# ATmega162 register map
Vendor: Atmel; File version: 1.0
CPU: other r0p0, little endian, no MPU, no FPU, 4 interrupt priority bits
Registers are 8-bit, read-write, reset 0x0 unless marked. A register's access mark holds for its fields unless they carry their own. Offsets are from the block's base; [hi:lo] are bit positions.

## TC3 — Timer/Counter, 16-bit
Base 0x0000007C
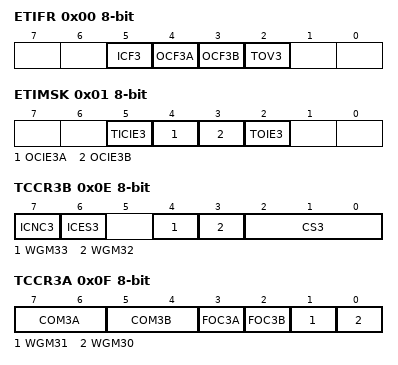
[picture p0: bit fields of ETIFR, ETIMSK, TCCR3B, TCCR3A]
0x00 ETIFR — Extended Timer/Counter Interrupt Flag register
  [5] ICF3 — Input Capture Flag 3
  [4] OCF3A — Output Compare Flag 3A
  [3] OCF3B — Output Compare Flag 3B
  [2] TOV3 — Timer/Counter3 Overflow Flag
0x01 ETIMSK — Extended Timer/Counter Interrupt Mask Register
  [5] TICIE3 — Timer/Counter3 Input Capture Interrupt Enable
  [4] OCIE3A — Timer/Counter3 Output CompareA Match Interrupt Enable
  [3] OCIE3B — Timer/Counter3 Output CompareB Match Interrupt Enable
  [2] TOIE3 — Timer/Counter3 Overflow Interrupt Enable
0x04 ICR3 16-bit (reset mask 0xFF) — Timer/Counter3 Input Capture Register Bytes
0x08 OCR3B 16-bit (reset mask 0xFF) — Timer/Counte3 Output Compare Register B Bytes
0x0A OCR3A 16-bit (reset mask 0xFF) — Timer/Counter3 Output Compare Register A Bytes
0x0C TCNT3 16-bit (reset mask 0xFF) — Timer/Counter3 Bytes
0x0E TCCR3B — Timer/Counter3 Control Register B
  [7] ICNC3 — Input Capture 3 Noise Canceler
  [6] ICES3 — Input Capture 3 Edge Select
  [4] WGM33 — Waveform Generation Mode
  [3] WGM32 — Waveform Generation Mode
  [2:0] CS3 — Clock Select3 bits
    0=No Clock Source (Stopped); 1=Running, No Prescaling; 2=Running, CLK/8; 3=Running, CLK/64; 4=Running, CLK/256; 5=Running, CLK/1024; 6=Running, CLK/16; 7=Running, CLK/32
0x0F TCCR3A — Timer/Counter3 Control Register A
  [7:6] COM3A — Compare Output Mode 3A, bits
  [5:4] COM3B — Compare Output Mode 3B, bits
  [3] FOC3A — Force Output Compare for Channel A
  [2] FOC3B — Force Output Compare for Channel B
  [1] WGM31 — Waveform Generation Mode
  [0] WGM30 — Waveform Generation Mode

## USART0 — USART
Base 0x00000029
0x00 UBRR0L — USART Baud Rate Register Low Byte
  [7:0] UBRR0 — USART Baud Rate Register Low bits
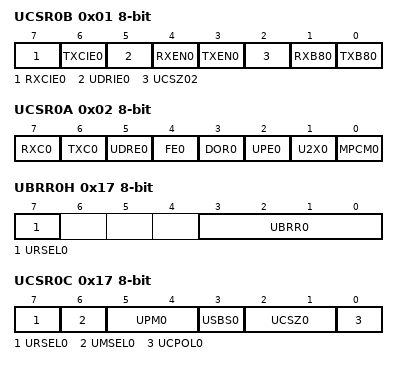
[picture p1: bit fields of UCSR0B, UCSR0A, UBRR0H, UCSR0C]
0x01 UCSR0B — USART Control and Status Register B
  [7] RXCIE0 — RX Complete Interrupt Enable
  [6] TXCIE0 — TX Complete Interrupt Enable
  [5] UDRIE0 — USART Data register Empty Interrupt Enable
  [4] RXEN0 — Receiver Enable
  [3] TXEN0 — Transmitter Enable
  [2] UCSZ02 — Character Size
  [1] RXB80 — Receive Data Bit 8
  [0] TXB80 — Transmit Data Bit 8
0x02 UCSR0A — USART Control and Status Register A
  [7] RXC0 — USART Receive Complete
  [6] TXC0 — USART Transmitt Complete
  [5] UDRE0 — USART Data Register Empty
  [4] FE0 — Framing Error
  [3] DOR0 — Data overRun
  [2] UPE0 — Parity Error
  [1] U2X0 — Double the USART transmission speed
  [0] MPCM0 — Multi-processor Communication Mode
0x03 UDR0 — USART I/O Data Register
0x17 UBRR0H — USART Baud Rate Register High Byte
  [7] URSEL0 — Register Select
  [3:0] UBRR0 — USART Baud Rate Register High bits
0x17 UCSR0C — USART Control and Status Register C
  [7] URSEL0 — Register Select
  [6] UMSEL0 — USART Mode Select
    0=Asynchronous Operation; 1=Synchronous Operation
  [5:4] UPM0 — Parity Mode Bits
    0=Disabled; 2=Enabled, Even Parity; 3=Enabled, Odd Parity
  [3] USBS0 — Stop Bit Select
    0=1-bit; 1=2-bit
  [2:1] UCSZ0 — Character Size
  [0] UCPOL0 — Clock Polarity

## USART1 — USART
Base 0x00000020
0x00 UBRR1L — USART Baud Rate Register Low Byte
  [7:0] UBRR1 — USART Baud Rate Register Low bits
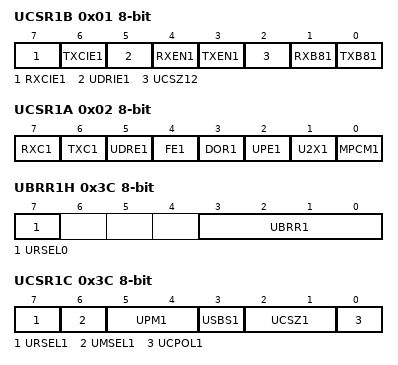
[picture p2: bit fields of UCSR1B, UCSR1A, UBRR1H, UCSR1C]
0x01 UCSR1B — USART Control and Status Register B
  [7] RXCIE1 — RX Complete Interrupt Enable
  [6] TXCIE1 — TX Complete Interrupt Enable
  [5] UDRIE1 — USART Data register Empty Interrupt Enable
  [4] RXEN1 — Receiver Enable
  [3] TXEN1 — Transmitter Enable
  [2] UCSZ12 — Character Size
  [1] RXB81 — Receive Data Bit 8
  [0] TXB81 — Transmit Data Bit 8
0x02 UCSR1A — USART Control and Status Register A
  [7] RXC1 — USART Receive Complete
  [6] TXC1 — USART Transmitt Complete
  [5] UDRE1 — USART Data Register Empty
  [4] FE1 — Framing Error
  [3] DOR1 — Data overRun
  [2] UPE1 — Parity Error
  [1] U2X1 — Double the USART transmission speed
  [0] MPCM1 — Multi-processor Communication Mode
0x03 UDR1 — USART I/O Data Register
0x3C UBRR1H — USART Baud Rate Register Highg Byte
  [7] URSEL0 — Register Select
  [3:0] UBRR1 — USART Baud Rate Register High bits
0x3C UCSR1C — USART Control and Status Register C
  [7] URSEL1 — Register Select
  [6] UMSEL1 — USART Mode Select
    0=Asynchronous Operation; 1=Synchronous Operation
  [5:4] UPM1 — Parity Mode Bits
    0=Disabled; 2=Enabled, Even Parity; 3=Enabled, Odd Parity
  [3] USBS1 — Stop Bit Select
    0=1-bit; 1=2-bit
  [2:1] UCSZ1 — Character Size
  [0] UCPOL1 — Clock Polarity

## WDT — Watchdog Timer
Base 0x00000041
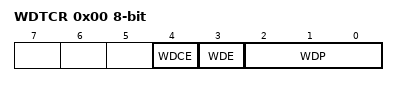
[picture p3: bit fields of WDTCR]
0x00 WDTCR — Watchdog Timer Control Register
  [4] WDCE — Watchdog Change Enable
  [3] WDE — Watch Dog Enable
  [2:0] WDP — Watch Dog Timer Prescaler bits
    0=Oscillator Cycles 16K; 1=Oscillator Cycles 32K; 2=Oscillator Cycles 64K; 3=Oscillator Cycles 128K; 4=Oscillator Cycles 256K; 5=Oscillator Cycles 512K; 6=Oscillator Cycles 1024K; 7=Oscillator Cycles 2048K
